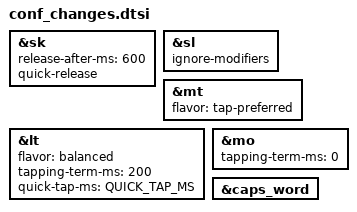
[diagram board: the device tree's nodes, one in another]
/* config changes */

&sk {  // sticky-key
    release-after-ms = <600>;
    quick-release;
};

&sl {  // sticky-layer
    ignore-modifiers;
};

&mt {
    flavor = "tap-preferred";
};
&lt {  // layer-tap
    flavor = "balanced";
    tapping-term-ms = <200>;
    quick-tap-ms = <QUICK_TAP_MS>;
};

&mo {
    tapping-term-ms = <0>;
}

&caps_word {  // mods deactivate caps-word, requires PR #1441
    /delete-property/ ignore-modifiers;
};
